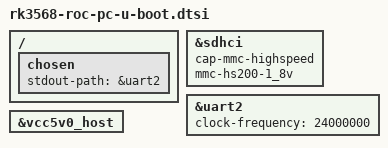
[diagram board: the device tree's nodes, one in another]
// SPDX-License-Identifier: GPL-2.0-or-later OR MIT

#include "rk356x-u-boot.dtsi"

/ {
	chosen {
		stdout-path = &uart2;
	};
};

&sdhci {
	cap-mmc-highspeed;
	mmc-hs200-1_8v;
};

&uart2 {
	clock-frequency = <24000000>;
	bootph-all;
	status = "okay";
};

&vcc5v0_host {
	/delete-property/ regulator-always-on;
};
